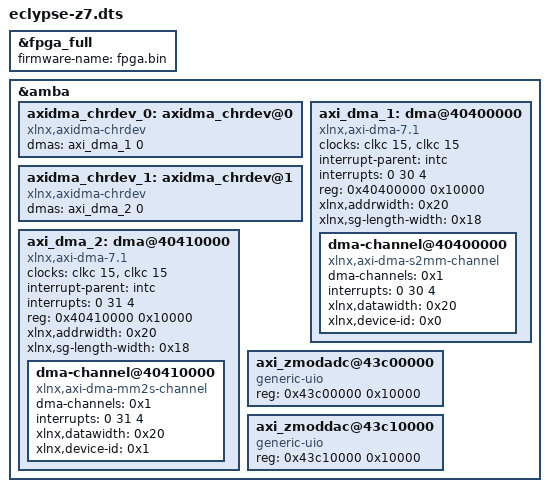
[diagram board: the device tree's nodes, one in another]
/dts-v1/;
/plugin/;
/ {
    fragment@0 {
      target = <&fpga_full>;
      overlay0: __overlay__ {
        #address-cells = <1>;
        #size-cells = <1>;
        firmware-name = "fpga.bin";
      };
    };
    fragment@1 {
      target = <&amba>;
      overlay1: __overlay__ {
        #address-cells = <1>;
        #size-cells = <1>;
        axidma_chrdev_0: axidma_chrdev@0 {
          compatible = "xlnx,axidma-chrdev";
          dmas = <&axi_dma_1 0>;
          dma-names = "rx_channel";
        };
        axidma_chrdev_1: axidma_chrdev@1 {
          compatible = "xlnx,axidma-chrdev";
          dmas = <&axi_dma_2 0>;
          dma-names = "tx_channel";
        };
        axi_dma_1: dma@40400000 {
          #dma-cells = <1>;
          clock-names = "s_axi_lite_aclk", "m_axi_s2mm_aclk";
          clocks = <&clkc 15>, <&clkc 15>;
          compatible = "xlnx,axi-dma-7.1", "xlnx,axi-dma-1.00.a";
          interrupt-names = "s2mm_introut";
          interrupt-parent = <&intc>;
          interrupts = <0 30 4>;
          reg = <0x40400000 0x10000>;
          xlnx,addrwidth = <0x20>;
          xlnx,sg-length-width = <0x18>;
          dma-channel@40400000 {
            compatible = "xlnx,axi-dma-s2mm-channel";
            dma-channels = <0x1>;
            interrupts = <0 30 4>;
            xlnx,datawidth = <0x20>;
            xlnx,device-id = <0x0>;
          };
        };
        axi_dma_2: dma@40410000 {
          #dma-cells = <1>;
          clock-names = "s_axi_lite_aclk", "m_axi_mm2s_aclk";
          clocks = <&clkc 15>, <&clkc 15>;
          compatible = "xlnx,axi-dma-7.1", "xlnx,axi-dma-1.00.a";
          interrupt-names = "mm2s_introut";
          interrupt-parent = <&intc>;
          interrupts = <0 31 4>;
          reg = <0x40410000 0x10000>;
          xlnx,addrwidth = <0x20>;
          xlnx,sg-length-width = <0x18>;
          dma-channel@40410000 {
            compatible = "xlnx,axi-dma-mm2s-channel";
            dma-channels = <0x1>;
            interrupts = <0 31 4>;
            xlnx,datawidth = <0x20>;
            xlnx,device-id = <0x1>;
          };
        };
        axi_zmodadc@43c00000 {
            compatible = "generic-uio";
                reg = <0x43c00000 0x10000>;
        };
        axi_zmoddac@43c10000 {
            compatible = "generic-uio";
                reg = <0x43c10000 0x10000>;
        };
      };
    };
  };
